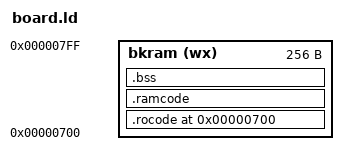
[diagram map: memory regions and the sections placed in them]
/*******************************************************************************
*
* Filename:	./board.ld
*
* Project:	ICO Zip, iCE40 ZipCPU demonstration project
*
* DO NOT EDIT THIS FILE!
* Computer Generated: This file is computer generated by AUTOFPGA. DO NOT EDIT.
* DO NOT EDIT THIS FILE!
*
* CmdLine:	autofpga autofpga -o . global.txt bkram.txt buserr.txt clock.txt pic.txt pwrcount.txt version.txt hbconsole.txt gpio.txt dlyarbiter.txt zipbones.txt
*
* Creator:	Dan Gisselquist, Ph.D.
*		Gisselquist Technology, LLC
*
/*******************************************************************************
*
* Copyright (C) 2017, Gisselquist Technology, LLC
*
* This program is free software (firmware): you can redistribute it and/or
* modify it under the terms of  the GNU General Public License as published
* by the Free Software Foundation, either version 3 of the License, or (at
* your option) any later version.
*
* This program is distributed in the hope that it will be useful, but WITHOUT
* ANY WARRANTY; without even the implied warranty of MERCHANTIBILITY or
* FITNESS FOR A PARTICULAR PURPOSE.  See the GNU General Public License
* for more details.
*
* You should have received a copy of the GNU General Public License along
* with this program.  (It's in the $(ROOT)/doc directory.  Run make with no
* target there if the PDF file isn't present.)  If not, see
* <http://www.gnu.org/licenses/> for a copy.
*
* License:	GPL, v3, as defined and found on www.gnu.org,
*		http://www.gnu.org/licenses/gpl.html
*
*
/*******************************************************************************
*
*
*/
ENTRY(_start)

MEMORY
{
	   bkram(wx) : ORIGIN = 0x00000700, LENGTH = 0x00000100
}

_bkram    = ORIGIN(bkram);
SECTIONS
{
	.rocode 0x00000700 : ALIGN(4) {
		_boot_address = .;
		*(.start) *(.boot)
	} > bkram
	_kernel_image_start = . ;
	_kernel_image_end = . ;
	_ram_image_start = . ;
	.ramcode : ALIGN_WITH_INPUT {
		*(.kernel)
		*(.text.startup)
		*(.text*)
		*(.rodata*) *(.strings)
		*(.data) *(COMMON)
		}> bkram
	_ram_image_end = . ;
	.bss : ALIGN_WITH_INPUT {
		*(.bss)
		_bss_image_end = . ;
		} > bkram
	_top_of_heap = .;
}
